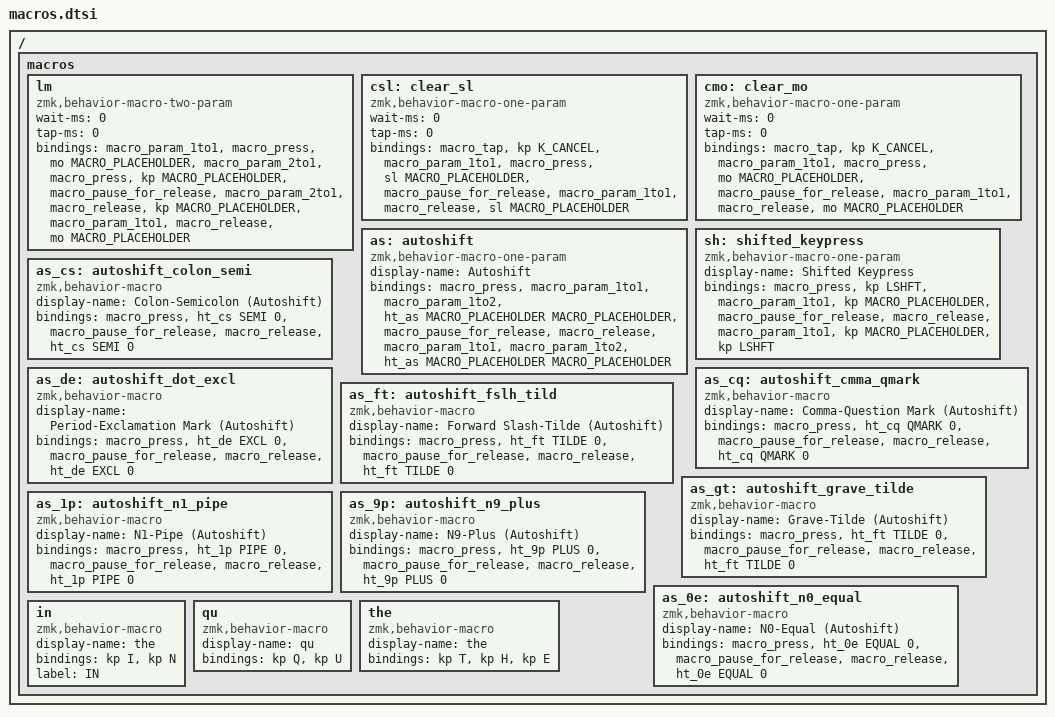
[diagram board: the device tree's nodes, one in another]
/ {
    macros {
		/*
			Temporarily switches to a layer (&mo) while a modifier is held. This
			is an implementation of QMK's `LM()` using ZMK's parameterized macros.

			Params:
				1. Layer to switch to
				2. Modifier to press while layer is active

			Example:
				`&lm L1 LSHIFT`
		*/
		/omit-if-no-ref/ lm: lm {
			wait-ms = <0>;
			tap-ms = <0>;
			compatible = "zmk,behavior-macro-two-param";
			#binding-cells = <2>;
			bindings = <&macro_param_1to1>,
				<&macro_press &mo MACRO_PLACEHOLDER>,
				<&macro_param_2to1>,
				<&macro_press &kp MACRO_PLACEHOLDER>,
				<&macro_pause_for_release>,
				<&macro_param_2to1>,
				<&macro_release &kp MACRO_PLACEHOLDER>,
				<&macro_param_1to1>,
				<&macro_release &mo MACRO_PLACEHOLDER>;
		};

		/*
			Practically identical to &sl, except it triggers a `K_CANCEL` right
			before to clear any active smart layers. This prevents nested/stacked
			layer activation when needed.

			Params:
				1. Layer to switch to

			Example:
				`&csl L1`
		*/
		/omit-if-no-ref/ csl: clear_sl {
			wait-ms = <0>;
			tap-ms = <0>;
			compatible = "zmk,behavior-macro-one-param";
			#binding-cells = <1>;
			bindings = <&macro_tap &kp K_CANCEL>,
				<&macro_param_1to1>,
				<&macro_press &sl MACRO_PLACEHOLDER>,
				<&macro_pause_for_release>,
				<&macro_param_1to1>,
				<&macro_release &sl MACRO_PLACEHOLDER>;
		};

		/*
			Practically identical to &mo, except it triggers a `K_CANCEL` right
			before to clear any active smart layers. This prevents nested/stacked
			layer activation when needed. It's also useful to maintain more
			consistent expectations when holding a cancel/exit layer key from
			a smart layer.

			Params:
				1. Layer to switch to

			Example:
				`&cmo L1`
		*/
		/omit-if-no-ref/ cmo: clear_mo {
			wait-ms = <0>;
			tap-ms = <0>;
			compatible = "zmk,behavior-macro-one-param";
			#binding-cells = <1>;
			bindings = <&macro_tap &kp K_CANCEL>,
				<&macro_param_1to1>,
				<&macro_press &mo MACRO_PLACEHOLDER>,
				<&macro_pause_for_release>,
				<&macro_param_1to1>,
				<&macro_release &mo MACRO_PLACEHOLDER>;
		};

        /omit-if-no-ref/ as: autoshift {
            display-name = "Autoshift";
            compatible = "zmk,behavior-macro-one-param";
            #binding-cells = <1>;
            bindings =
                <&macro_press>,
                <&macro_param_1to1 &macro_param_1to2 &ht_as MACRO_PLACEHOLDER MACRO_PLACEHOLDER>,
                <&macro_pause_for_release>,
                <&macro_release>,
                <&macro_param_1to1 &macro_param_1to2 &ht_as MACRO_PLACEHOLDER MACRO_PLACEHOLDER>;
        };

        /omit-if-no-ref/ sh: shifted_keypress {
            display-name = "Shifted Keypress";
            compatible = "zmk,behavior-macro-one-param";
            #binding-cells = <1>;
            bindings =
                <&macro_press>,
                <&kp LSHFT &macro_param_1to1 &kp MACRO_PLACEHOLDER>,
                <&macro_pause_for_release>,
                <&macro_release>,
                <&macro_param_1to1 &kp MACRO_PLACEHOLDER &kp LSHFT>;
        };

        /omit-if-no-ref/ as_cq: autoshift_cmma_qmark {
            display-name = "Comma-Question Mark (Autoshift)";
            compatible = "zmk,behavior-macro";
            #binding-cells = <0>;
            bindings =
                <&macro_press>,
                <&ht_cq QMARK 0>,
                <&macro_pause_for_release>,
                <&macro_release>,
                <&ht_cq QMARK 0>;
        };

        /omit-if-no-ref/ as_cs: autoshift_colon_semi {
            compatible = "zmk,behavior-macro";
            display-name = "Colon-Semicolon (Autoshift)";
            #binding-cells = <0>;
            bindings =
                <&macro_press>,
                <&ht_cs SEMI 0>,
                <&macro_pause_for_release>,
                <&macro_release>,
                <&ht_cs SEMI 0>;
        };

        /omit-if-no-ref/ as_de: autoshift_dot_excl {
            display-name = "Period-Exclamation Mark (Autoshift)";
            compatible = "zmk,behavior-macro";
            #binding-cells = <0>;
            bindings =
                <&macro_press>,
                <&ht_de EXCL 0>,
                <&macro_pause_for_release>,
                <&macro_release>,
                <&ht_de EXCL 0>;
        };

        /omit-if-no-ref/ as_ft: autoshift_fslh_tild {
            display-name = "Forward Slash-Tilde (Autoshift)";
            compatible = "zmk,behavior-macro";
            #binding-cells = <0>;
            bindings =
                <&macro_press>,
                <&ht_ft TILDE 0>,
                <&macro_pause_for_release>,
                <&macro_release>,
                <&ht_ft TILDE 0>;
        };

        /omit-if-no-ref/ as_gt: autoshift_grave_tilde {
            display-name = "Grave-Tilde (Autoshift)";
            compatible = "zmk,behavior-macro";
            #binding-cells = <0>;
            bindings =
                <&macro_press>,
                <&ht_ft TILDE 0>,
                <&macro_pause_for_release>,
                <&macro_release>,
                <&ht_ft TILDE 0>;
        };

        /omit-if-no-ref/ as_1p: autoshift_n1_pipe {
            display-name = "N1-Pipe (Autoshift)";
            compatible = "zmk,behavior-macro";
            #binding-cells = <0>;
            bindings =
                <&macro_press>,
                <&ht_1p PIPE 0>,
                <&macro_pause_for_release>,
                <&macro_release>,
                <&ht_1p PIPE 0>;
        };

        /omit-if-no-ref/ as_9p: autoshift_n9_plus {
            display-name = "N9-Plus (Autoshift)";
            compatible = "zmk,behavior-macro";
            #binding-cells = <0>;
            bindings =
                <&macro_press>,
                <&ht_9p PLUS 0>,
                <&macro_pause_for_release>,
                <&macro_release>,
                <&ht_9p PLUS 0>;
        };

        /omit-if-no-ref/ as_0e: autoshift_n0_equal {
            display-name = "N0-Equal (Autoshift)";
            compatible = "zmk,behavior-macro";
            #binding-cells = <0>;
            bindings =
                <&macro_press>,
                <&ht_0e EQUAL 0>,
                <&macro_pause_for_release>,
                <&macro_release>,
                <&ht_0e EQUAL 0>;
        };

        /omit-if-no-ref/ in: in {
            compatible = "zmk,behavior-macro";
            display-name = "the";
            #binding-cells = <0>;
            bindings = <&kp I &kp N>;
            label = "IN";
        };

        /omit-if-no-ref/ qu: qu {
            display-name = "qu";
            compatible = "zmk,behavior-macro";
            #binding-cells = <0>;
            bindings = <&kp Q &kp U>;
        };

        /omit-if-no-ref/ the: the {
            display-name = "the";
            compatible = "zmk,behavior-macro";
            #binding-cells = <0>;
            bindings = <&kp T &kp H &kp E>;
        };
    };
};
